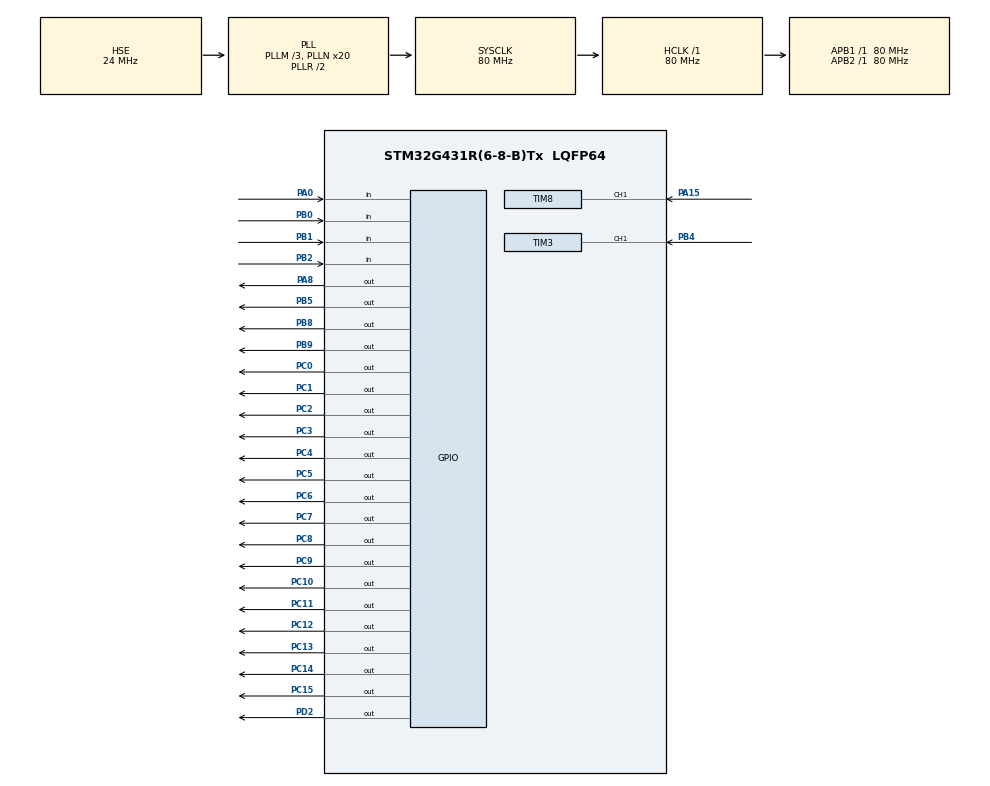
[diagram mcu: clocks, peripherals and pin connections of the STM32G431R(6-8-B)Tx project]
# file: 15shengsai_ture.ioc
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Dma.Request0=TIM3_CH1
Dma.Request1=TIM8_CH1
Dma.TIM3_CH1.0.Direction=DMA_PERIPH_TO_MEMORY
Dma.TIM3_CH1.0.EventEnable=DISABLE
Dma.TIM3_CH1.0.Instance=DMA1_Channel1
Dma.TIM3_CH1.0.MemDataAlignment=DMA_MDATAALIGN_WORD
Dma.TIM3_CH1.0.MemInc=DMA_MINC_ENABLE
Dma.TIM3_CH1.0.Mode=DMA_CIRCULAR
Dma.TIM3_CH1.0.PeriphDataAlignment=DMA_PDATAALIGN_WORD
Dma.TIM3_CH1.0.PeriphInc=DMA_PINC_DISABLE
Dma.TIM3_CH1.0.Polarity=HAL_DMAMUX_REQ_GEN_RISING
Dma.TIM3_CH1.0.Priority=DMA_PRIORITY_LOW
Dma.TIM3_CH1.0.RequestNumber=1
Dma.TIM3_CH1.0.SignalID=NONE
Dma.TIM3_CH1.0.SyncEnable=DISABLE
Dma.TIM3_CH1.0.SyncPolarity=HAL_DMAMUX_SYNC_NO_EVENT
Dma.TIM3_CH1.0.SyncRequestNumber=1
Dma.TIM3_CH1.0.SyncSignalID=NONE
Dma.TIM8_CH1.1.Direction=DMA_PERIPH_TO_MEMORY
Dma.TIM8_CH1.1.EventEnable=DISABLE
Dma.TIM8_CH1.1.Instance=DMA1_Channel2
Dma.TIM8_CH1.1.MemDataAlignment=DMA_MDATAALIGN_WORD
Dma.TIM8_CH1.1.MemInc=DMA_MINC_ENABLE
Dma.TIM8_CH1.1.Mode=DMA_CIRCULAR
Dma.TIM8_CH1.1.PeriphDataAlignment=DMA_PDATAALIGN_WORD
Dma.TIM8_CH1.1.PeriphInc=DMA_PINC_DISABLE
Dma.TIM8_CH1.1.Polarity=HAL_DMAMUX_REQ_GEN_RISING
Dma.TIM8_CH1.1.Priority=DMA_PRIORITY_LOW
Dma.TIM8_CH1.1.RequestNumber=1
Dma.TIM8_CH1.1.SignalID=NONE
Dma.TIM8_CH1.1.SyncEnable=DISABLE
Dma.TIM8_CH1.1.SyncPolarity=HAL_DMAMUX_SYNC_NO_EVENT
Dma.TIM8_CH1.1.SyncRequestNumber=1
Dma.TIM8_CH1.1.SyncSignalID=NONE
Mcu.Family=STM32G4
Mcu.Name=STM32G431R(6-8-B)Tx
Mcu.Package=LQFP64
NVIC.DMA1_Channel1_IRQn=true\:0\:0\:false\:false\:true\:false\:true\:true
NVIC.DMA1_Channel2_IRQn=true\:0\:0\:false\:false\:true\:false\:true\:true
NVIC.PriorityGroup=NVIC_PRIORITYGROUP_4
PA0.GPIO_PuPd=GPIO_PULLUP
PA0.Signal=GPIO_Input
PA15.Signal=S_TIM8_CH1
PA8.Signal=GPIO_Output
PB0.GPIO_PuPd=GPIO_PULLUP
PB0.Signal=GPIO_Input
PB1.GPIO_PuPd=GPIO_PULLUP
PB1.Signal=GPIO_Input
PB2.GPIO_PuPd=GPIO_PULLUP
PB2.Signal=GPIO_Input
PB4.Signal=S_TIM3_CH1
PB5.Signal=GPIO_Output
PB8-BOOT0.Signal=GPIO_Output
PB9.Signal=GPIO_Output
PC0.Signal=GPIO_Output
PC1.Signal=GPIO_Output
PC10.Signal=GPIO_Output
PC11.Signal=GPIO_Output
PC12.Signal=GPIO_Output
PC13.Signal=GPIO_Output
PC14-OSC32_IN.Signal=GPIO_Output
PC15-OSC32_OUT.Signal=GPIO_Output
PC2.Signal=GPIO_Output
PC3.Signal=GPIO_Output
PC4.Signal=GPIO_Output
PC5.Signal=GPIO_Output
PC6.Signal=GPIO_Output
PC7.Signal=GPIO_Output
PC8.Signal=GPIO_Output
PC9.Signal=GPIO_Output
PD2.Signal=GPIO_Output
PF0-OSC_IN.Mode=HSE-External-Oscillator
PF0-OSC_IN.Signal=RCC_OSC_IN
PF1-OSC_OUT.Mode=HSE-External-Oscillator
PF1-OSC_OUT.Signal=RCC_OSC_OUT
ProjectManager.HeapSize=0x200
ProjectManager.StackSize=0x400
ProjectManager.TargetToolchain=MDK-ARM V5.32
RCC.ADC12Freq_Value=80000000
RCC.AHBFreq_Value=80000000
RCC.APB1Freq_Value=80000000
RCC.APB1TimFreq_Value=80000000
RCC.APB2Freq_Value=80000000
RCC.APB2TimFreq_Value=80000000
RCC.CortexFreq_Value=80000000
RCC.EXTERNAL_CLOCK_VALUE=12288000
RCC.HCLKFreq_Value=80000000
RCC.HSE_VALUE=24000000
RCC.HSI48_VALUE=48000000
RCC.HSI_VALUE=16000000
RCC.LSE_VALUE=32768
RCC.PLLM=RCC_PLLM_DIV3
RCC.PLLN=20
RCC.PLLSourceVirtual=RCC_PLLSOURCE_HSE
RCC.SYSCLKFreq_VALUE=80000000
RCC.SYSCLKSource=RCC_SYSCLKSOURCE_PLLCLK
RCC.USBFreq_Value=80000000
RCC.VCOOutputFreq_Value=160000000
SH.S_TIM3_CH1.0=TIM3_CH1,Input_Capture1_from_TI1
SH.S_TIM3_CH1.1=TIM3_CH1,TriggerSource_TI1FP1
SH.S_TIM8_CH1.0=TIM8_CH1,TriggerSource_TI1FP1
SH.S_TIM8_CH1.1=TIM8_CH1,Input_Capture1_from_TI1
TIM3.Channel-Input_Capture1_from_TI1=TIM_CHANNEL_1
TIM3.Prescaler=79
TIM8.Channel-Input_Capture1_from_TI1=TIM_CHANNEL_1
TIM8.Prescaler=79
VP_SYS_VS_DBSignals.Mode=DisableDeadBatterySignals
VP_TIM3_VS_ClockSourceINT.Mode=Internal
VP_TIM3_VS_ControllerModeReset.Mode=Reset Mode
VP_TIM8_VS_ClockSourceINT.Mode=Internal
VP_TIM8_VS_ControllerModeReset.Mode=Reset Mode
board=custom

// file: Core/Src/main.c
/* USER CODE BEGIN Header */
/**
  ******************************************************************************
  * @file           : main.c
  * @brief          : Main program body
  ******************************************************************************
  * @attention
  *
  * Copyright (c) 2025 STMicroelectronics.
  * All rights reserved.
  *
  * This software is licensed under terms that can be found in the LICENSE file
  * in the root directory of this software component.
  * If no LICENSE file comes with this software, it is provided AS-IS.
  *
  ******************************************************************************
  */
/* USER CODE END Header */
#include "main.h"
#include "dma.h"
#include "tim.h"
#include "gpio.h"
#include "bsp.h"

void SystemClock_Config(void);

int main(void)
{

  /* MCU Configuration--------------------------------------------------------*/

  /* Reset of all peripherals, Initializes the Flash interface and the Systick. */
  HAL_Init();

  /* Configure the system clock */
  SystemClock_Config();

  /* Initialize all configured peripherals */
  MX_GPIO_Init();
  MX_DMA_Init();
  MX_TIM3_Init();
  MX_TIM8_Init();
	LCD_Init();
	LCD_Clear(Black);
	LCD_SetBackColor(Black);
	LCD_SetTextColor(White);
	HAL_TIM_IC_Start_DMA(&htim3,TIM_CHANNEL_1,tim_ic_buffer[1],64);//PB4  R39 B
	HAL_TIM_IC_Start_DMA(&htim8,TIM_CHANNEL_1,tim_ic_buffer[0],64);//PA15 R40 A
  /* USER CODE BEGIN 2 */
scheduler_init();
  /* USER CODE END 2 */

  /* Infinite loop */
  while (1)
  {
//lcd_proc();
//ic_proc();
//key_proc();
//led_proc();
scheduler_run();
  }
}

void SystemClock_Config(void)
{
  RCC_OscInitTypeDef RCC_OscInitStruct = {0};
  RCC_ClkInitTypeDef RCC_ClkInitStruct = {0};

  /** Configure the main internal regulator output voltage
  */
  HAL_PWREx_ControlVoltageScaling(PWR_REGULATOR_VOLTAGE_SCALE1);

  /** Initializes the RCC Oscillators according to the specified parameters
  * in the RCC_OscInitTypeDef structure.
  */
  RCC_OscInitStruct.OscillatorType = RCC_OSCILLATORTYPE_HSE;
  RCC_OscInitStruct.HSEState = RCC_HSE_ON;
  RCC_OscInitStruct.PLL.PLLState = RCC_PLL_ON;
  RCC_OscInitStruct.PLL.PLLSource = RCC_PLLSOURCE_HSE;
  RCC_OscInitStruct.PLL.PLLM = RCC_PLLM_DIV3;
  RCC_OscInitStruct.PLL.PLLN = 20;
  RCC_OscInitStruct.PLL.PLLP = RCC_PLLP_DIV2;
  RCC_OscInitStruct.PLL.PLLQ = RCC_PLLQ_DIV2;
  RCC_OscInitStruct.PLL.PLLR = RCC_PLLR_DIV2;
  if (HAL_RCC_OscConfig(&RCC_OscInitStruct) != HAL_OK)
  {
    Error_Handler();
  }

  /** Initializes the CPU, AHB and APB buses clocks
  */
  RCC_ClkInitStruct.ClockType = RCC_CLOCKTYPE_HCLK|RCC_CLOCKTYPE_SYSCLK
                              |RCC_CLOCKTYPE_PCLK1|RCC_CLOCKTYPE_PCLK2;
  RCC_ClkInitStruct.SYSCLKSource = RCC_SYSCLKSOURCE_PLLCLK;
  RCC_ClkInitStruct.AHBCLKDivider = RCC_SYSCLK_DIV1;
  RCC_ClkInitStruct.APB1CLKDivider = RCC_HCLK_DIV1;
  RCC_ClkInitStruct.APB2CLKDivider = RCC_HCLK_DIV1;

  if (HAL_RCC_ClockConfig(&RCC_ClkInitStruct, FLASH_LATENCY_2) != HAL_OK)
  {
    Error_Handler();
  }
}

void Error_Handler(void)
{
  __disable_irq();
  while (1)
  {
  }
}
